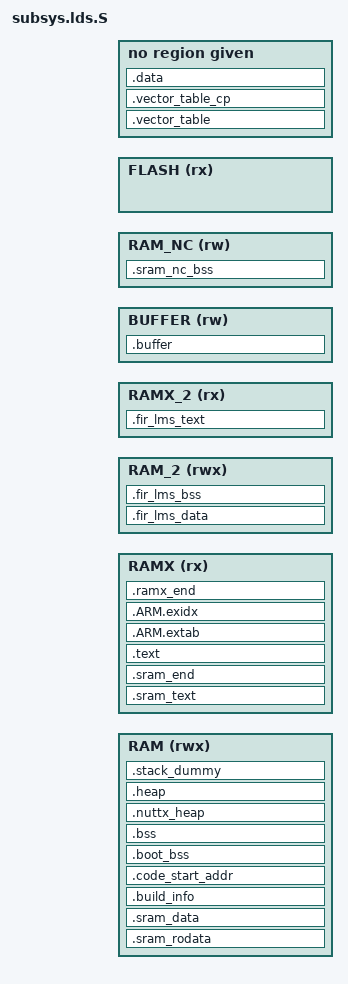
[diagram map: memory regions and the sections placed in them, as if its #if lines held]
/***************************************************************************
 *
 * Copyright 2015-2020 BES.
 * All rights reserved. All unpublished rights reserved.
 *
 * No part of this work may be used or reproduced in any form or by any
 * means, or stored in a database or retrieval system, without prior written
 * permission of BES.
 *
 * Use of this work is governed by a license granted by BES.
 * This work contains confidential and proprietary information of
 * BES. which is protected by copyright, trade secret,
 * trademark and other intellectual property rights.
 *
 ****************************************************************************/

#include "plat_addr_map.h"

#define HEAP_SECTION_SIZE			0x400
#if defined(__NuttX__)
#include "nuttx/config.h"
#define NUTTX_HEAP_SECTION_SIZE		0x10000
#ifdef HEAP_SECTION_SIZE
#undef HEAP_SECTION_SIZE
#define HEAP_SECTION_SIZE			0x10
#endif
#define STACK_SECTION_SIZE			CONFIG_IDLETHREAD_STACKSIZE
#define NUTTX_HEAP_USE_MAX          (37 * 1024)
#else
#define STACK_SECTION_SIZE			0x1100
#endif

#ifndef CP_STACK_SECTION_SIZE
#define CP_STACK_SECTION_SIZE       0x1000
#endif

#ifndef MAIN_RAM_USE_TCM
#ifndef NO_OVERLAY
#error "Overlay is NOT supported unless MAIN_RAM_USE_TCM defined"
#endif
#ifndef RAMXRET_SIZE
#define RAMXRET_SIZE				RAMRET_SIZE
#endif
#ifndef RAMX_SIZE
#define RAMX_SIZE					RAM_SIZE
#endif
#endif

#ifdef FLASH_BASE
#if !defined(OTA_BOOT_SIZE) && defined(OTA_CODE_OFFSET)
#define FLASH_REGION_BASE			(FLASH_BASE + OTA_CODE_OFFSET)
#elif defined(OTA_BOOT_OFFSET)
#define FLASH_REGION_BASE			(FLASH_BASE + OTA_BOOT_OFFSET)
#else
#define FLASH_REGION_BASE			(FLASH_BASE)
#endif

#ifndef FLASH_REGION_SIZE
#define FLASH_REGION_SIZE			(FLASH_SIZE - (FLASH_REGION_BASE - FLASH_BASE))
#endif
#endif

#ifdef MAIN_RAM_USE_TCM
#define LOAD_REGION					FLASH
#else
#define LOAD_REGION					RAM
#endif

#ifdef RAM_NC_BASE
#define REGION_VECTOR				RAM_NC
#else
#define REGION_VECTOR				RAM
#endif

/* Linker script to configure memory regions. */
MEMORY
{
#if defined(RAMRET_SIZE) && (RAMRET_SIZE > 0)
	RAM		(rwx)	: ORIGIN = RAMRET_BASE,			LENGTH = RAMRET_SIZE
	RAMX	(rx)	: ORIGIN = RAMXRET_BASE,		LENGTH = RAMXRET_SIZE
#if (SENS_FIR_LMS_SIZE > 0)
	RAM_2	(rwx)	: ORIGIN = RAMX_TO_RAM(SENS_FIR_LMS_BASE),	LENGTH = SENS_FIR_LMS_SIZE
	RAMX_2	(rx)	: ORIGIN = SENS_FIR_LMS_BASE,	LENGTH = SENS_FIR_LMS_SIZE
#endif
	BUFFER	(rw)	: ORIGIN = RAM_BASE,			LENGTH = RAM_SIZE
#else
	RAM		(rwx)	: ORIGIN = RAM_BASE,			LENGTH = RAM_SIZE
	RAMX	(rx)	: ORIGIN = RAMX_BASE,			LENGTH = RAMX_SIZE
#if (SENS_FIR_LMS_SIZE > 0)
	RAM_2	(rwx)	: ORIGIN = RAMX_TO_RAM(SENS_FIR_LMS_BASE),	LENGTH = SENS_FIR_LMS_SIZE
	RAMX_2	(rx)	: ORIGIN = SENS_FIR_LMS_BASE,	LENGTH = SENS_FIR_LMS_SIZE
#endif
#if SENS_PRI_RAM_AS_BUFFER_SECTION == 1
	BUFFER	(rw)	: ORIGIN = SENS_RAM6_BASE,	    LENGTH = (SENS_RAM6_SIZE+CODEC_VAD_MAX_BUF_SIZE)
#endif
#endif
#ifdef RAM_NC_BASE
	RAM_NC		(rw)	: ORIGIN = RAM_NC_BASE,		LENGTH = RAM_NC_SIZE
#endif
#ifdef FLASH_REGION_BASE
	FLASH 	(rx)	: ORIGIN = FLASH_REGION_BASE,	LENGTH = FLASH_REGION_SIZE
#endif
}

/* Library configurations */
#ifndef __NuttX__
GROUP(libgcc.a)
#endif

/* Linker script to place sections and symbol values. Should be used together
 * with other linker script that defines memory regions ROM and RAM.
 * It references following symbols, which must be defined in code:
 *   Reset_Handler : Entry of reset handler
 *
 * It defines following symbols, which code can use without definition:
 *   __exidx_start
 *   __exidx_end
 *   __etext
 *   __data_start__
 *   __data_end__
 *   __bss_start__
 *   __bss_end__
 *   __end__
 *   end
 *   __HeapLimit
 *   __StackLimit
 *   __StackTop
 *   __stack
 *   __free_ram
 *   __buffer_start__
 *   __buffer_end__
 *   __overlay_text_exec_start__
 *   __overlay_data_start__
 */
ENTRY(Reset_Handler)

SECTIONS
{
	.vector_table (ORIGIN(REGION_VECTOR)) (NOLOAD) :
	{
		KEEP(*(.vector_table))
		. = VECTOR_SECTION_SIZE;
		. = ALIGN(4);
		__vector_table_end__ = .;
	} > REGION_VECTOR

#if defined(CP_IN_SAME_EE) && (RAMCP_SIZE == 0)
    .vector_table_cp (NOLOAD) :
    {
        KEEP(*(.vector_table_cp))
        . = VECTOR_SECTION_SIZE;
        . = ALIGN(4);
        __vector_table_end__ = .;
    } > REGION_VECTOR
#endif

#ifdef RAM_NC_BASE
	.sram_nc_bss (NOLOAD) : AT (ADDR(.sram_nc_bss))
	{
		__sram_nc_bss_start__ = .;
		*(.sram_nc_bss*)
		*(.sync_flags_sram*)
		. = ALIGN(4);
		__sram_nc_bss_end__ = .;
	} > RAM_NC

	__ram_nc_top = ORIGIN(RAM_NC) + LENGTH(RAM_NC);
	__free_ram_nc = __ram_nc_top - __sram_nc_bss_end__;
#endif

#ifdef MAIN_RAM_USE_TCM
	__sram_text_start__ = ALIGN(ORIGIN(RAMX), 32);
	__sram_text_start_load__ = ORIGIN(LOAD_REGION);
	__sram_text_start_load_offset__ = 0;
#else
#ifdef RAM_NC_BASE
	.dummy_sram_text_start (NOLOAD) :
	{
		. = 32;
	} > RAMX
	__sram_text_start__ = ALIGN(., 32);
#else
	__sram_text_start__ = ALIGN(RAM_TO_RAMX(__vector_table_end__), 32);
#endif
	__sram_text_start_load__ = RAMX_TO_RAM(__sram_text_start__);
#endif

	.sram_text (__sram_text_start__) : AT (__sram_text_start_load__)
	{
		_stext = .;
		*(.reset_handler_subsys)
#ifdef NO_OVERLAY
#if (SENS_FIR_LMS_SIZE > 0)
        *(EXCLUDE_FILE(
			anc_fir_coeff_config_best1502x.o
			anc_fir_coeff_config_best1502p.o
			anc_ff_fir_lms.o
			arm_conj_cmplx_mult_cmplx_f32.o
			anc_optimal_tf.o
			mdf4.o
			kiss_fftwrap.o
			kiss_fftr.o
			kiss_fft.o
			anc_filter.o
			beco.o
			beco_fir_q15.o
            cmsis_dsp.o
			anc_fir_lms_aec.o
			) .text*)
			*:cmsis_dsp.o(.text*.arm_add_f32)
            *:cmsis_dsp.o(.text*.arm_copy_q31)
            *:cmsis_dsp.o(.text*.arm_conv_f32)
			*:cmsis_dsp.o(.text*.arm_rfft_fast_f32)
			*:cmsis_dsp.o(.text*.arm_fir_decimate_f32)
			*:cmsis_dsp.o(.text*.arm_biquad_cascade_df1_ex_f32)
#else
        *(.text*)
#endif
#endif
		*(.boot_text_sram*)
		*(.boot_text_flash*)
		*(.sram_text*)
		*(.fast_text_sram*)
		*(.flash_text*)

#ifndef NOSTD
		KEEP(*(.init))
		KEEP(*(.fini))

		/* .ctors */
		*crtbegin.o(.ctors)
		*crtbegin?.o(.ctors)
		*(EXCLUDE_FILE(*crtend?.o *crtend.o) .ctors)
		*(SORT(.ctors.*))
		*(.ctors)

		/* .dtors */
		*crtbegin.o(.dtors)
		*crtbegin?.o(.dtors)
		*(EXCLUDE_FILE(*crtend?.o *crtend.o) .dtors)
		*(SORT(.dtors.*))
		*(.dtors)
#endif
		. = ALIGN(4);
	} > RAMX

	.sram_end (.) : AT (LOADADDR(.sram_text) + SIZEOF(.sram_text))
	{
		. = ALIGN(32);
		__sram_text_end__ = .;
	} > RAMX

	__sram_text_seg_size__ = __sram_text_end__ - __sram_text_start__;

#ifdef NO_OVERLAY

	__text_start__ = __sram_text_end__;
	__text_load_start__ = LOADADDR(.sram_end) + SIZEOF(.sram_end);

#else

	__overlay_text_start__ = .;
	__overlay_text_exec_start__ = .;
	__overlay_load_text_start__ = LOADADDR(.sram_text) + SIZEOF(.sram_text);

	OVERLAY (__overlay_text_exec_start__) : NOCROSSREFS AT (__overlay_load_text_start__)
	{
		.overlay_text0
		{
			LONG(0);
#if defined(A2DP_DECODER_CROSS_CORE)
			*:a2dp_decoder_cc_sbc.o(.text*)
			*:sbc.o(.text*.sbc_is_stream_info_valid)
			*:sbc.o(.text*.sbc_frame_length_get)
			*:sbc.o(.text*.sbc_4bit_crc_calc)
			*:sbc.o(.text*.sbc_bits_for_mono_alloc)
			*:sbc.o(.text*.sbc_bits_for_stereo_alloc)
			*:sbc.o(.text*.sbc_header_process)
			*:sbc.o(.text*.sbc_factors_process)
			*:sbc.o(.text*.sbc_sample_extract)
			*:sbc.o(.text*.sbc_sbsamples_make)
			*:sbc.o(.text*.sbc_joint_process)
			*:sbc.o(.text*.sbc_4band_synth_filter)
			*:sbc.o(.text*.sbc_8band_synth_filter)
			*:sbc.o(.text*.sbc_decoder_state_reset)
			*:sbc.o(.text*.sbc_frame_mute)
			*:sbc.o(.text*.sbc_frames_decode)
			*:sbc.o(.text*.sbc_frames_decode_do)
			*:sbc.o(.text*.sbc_frames_decode_select_channel)
			*:sbc.o(.text*.sbc_frames_decode)
			*:sbc.o(.text*.sbc_samples_quant)
			*:sbc.o(.text*.sbc_decoder_init)
			*:sbc.o(.text*.sbc_encoder_init)
			*:sbc.o(.text*.sbc_frames_encode)
#endif
			*(.overlay_text0)
			. = ALIGN(4);
		}
		.overlay_text1
		{
			LONG(0);
#if defined(A2DP_DECODER_CROSS_CORE) && defined(A2DP_AAC_ON)
			*:a2dp_decoder_cc_aac.o(.text*)
			*:block.o(.text*.*CBlock_GetEscape*)
			*:tpdec_lib.o(.text*.*transportDec_GetBitstream*)
			*:tpdec_lib.o(.text*.*transportDec_GetAuBitsRemaining*)
			*:tpdec_latm.o(.text*.*CLatmDemux_GetValue*)
			*:tpdec_latm.o(.text*.*CLatmDemux_Read*)
			*:tpdec_lib.o(.text*.*transportDec_FillData*)
			*:tpdec_lib.o(.text*.*transportDec_ReadAccessUnit*)
			*:tpdec_lib.o(.text*.*transportDec_readHeader*)
			*:block.o(.text*.*ApplyTools*)
			*:aacdec_pns.o(.text*.*CPns_Apply*)
			*:aacdec_tns.o(.text*.*CTns_Apply*)
			*:aacdec_tns.o(.text*.*CTns_Reset*)
			*:aacdec_pns.o(.text*.*CPns_ResetData*)
			*:pulsedata.o(.text*.*CPulseData_Read*)
#if !defined(AAC_TEXT_PARTIAL_IN_FLASH)
			*:channel.o(.text*.*CChannelElement_Read*)
			*:tpdec_asc.o(.text*.*CProgramConfig_Reset*)
			*:tpdec_lib.o(.text*.*transportDec_CrcCheck*)
			*:block.o(.text*.*CBlock_FrequencyToTime*)
			*:block.o(.text*.*CBlock_ReadSectionData*)
			*:channel.o(.text*.*CChannelElement_Decode*)
			*:tpdec_lib.o(.text*.*transportDec_CrcEndReg*)
			*:aacdecoder.o(.text*.*CAacDecoder_DecodeFrame*)
			*:aac_mdct.o(.text*)
#endif

#if !defined(__SBC_FUNC_IN_ROM_VBEST2000__) && !defined(AAC_TEXT_PARTIAL_IN_FLASH)
			*:block.o(.text*.*CBlock_ReadSpectralData*)
			*:block.o(.text*.*CBlock_ScaleSpectralData*)
			*:aacdec_tns.o(.text*.*CTns_ReadDataPresentFlag*)
			*:tpdec_lib.o(.text*.*transportDec_CrcStartReg*)
			*:block.o(.text*.*CBlock_ReadScaleFactorData*)
			*:tpdec_lib.o(.text*.*transportDec_EndAccessUnit*)
			*:tpdec_latm.o(.text*.*CLatmDemux_GetNrOfSubFrames*)
			*:tpdec_lib.o(.text*.*transportDec_GetAuBitsTotal*)
			*:tpdec_asc.o(.text*.*CProgramConfig_LookupElement*)
			*:tpdec_latm.o(.text*.*CLatmDemux_GetFrameLengthInBits*)
			*:tpdec_latm.o(.text*.*CLatmDemux_ReadPayloadLengthInfo*)
			*:block.o(.text*.*CBlock_InverseQuantizeSpectralData*)
			*:channelinfo.o(.text*.*IcsRead*)
			*:aacdec_tns.o(.text*.*CTns_Read*)
			*:tpdec_lib.o(.text*.*transportDec_AdjustEndOfAccessUnit*)
			*:pulsedata.o(.text*.*CPulseData_Apply*)
			*:tpdec_asc.o(.text*.*AudioSpecificConfig_Init*)
			*:tpdec_asc.o(.text*.*AudioSpecificConfig_Parse*)
			*:tpdec_latm.o(.text*.*CLatmDemux_ReadStreamMuxConfig*)
			*:tpdec_asc.o(.text*.*getSampleRate*)
			*:tpdec_asc.o(.text*.*getAOT*)
			*:aacdecoder.o(.text*.*CAacDecoder_Init*)
			*:tpdec_asc.o(.text*.*CProgramConfig_Init*)
			*:aacdecoder_lib.o(.text*.*aacDecoder_ConfigCallback*)
			*:aacdecoder.o(.text*.*CAacDecoder_ExtPayloadParse*)
			*:stereo.o(.text*.*CJointStereo_Read*)
#endif			
			*:aac_com.o(.text*)
			*:aac_enc.o(.text*)
			*:aac_dec.o(.text*)
#endif
			*(.overlay_text1)
			. = ALIGN(4);
		}
		.overlay_text2
		{
			LONG(0);
#if defined(A2DP_DECODER_CROSS_CORE) && defined(A2DP_SCALABLE_ON)
			*:rc_decode.o(.text*)
			*:audio_int32.o(.text*)
			*:ssc_ifft.o(.text*)
			*:vector_quant.o(.text*)
			*:ssc_quant.o(.text*)
			*:ssc_pulsealloc.o(.text*)
			*:audio.o(.text*)
			*:set_sbm.o(.text*)
			*:rc_code.o(.text*)
			*:SBM_pitchBased.o(.text*)
			*:ssc_imdct.o(.text*)
			*:audio_decoder.o(.text*)
			*:SoundBooster_DRC_classic.o(.text*)
			*:ssc_cwrs.o(.text*)
			*:ssc_mode.o(.text*)
			*:ssc_math.o(.text*)
			*:ssc_lap.o(.text*)
			*:SeamlessBufferManagement.o(.text*)
			*:a2dp_decoder_cc_scalable.o(.text*)
#endif
			*(.overlay_text2)
			. = ALIGN(4);
		}
		.overlay_text3
		{
			LONG(0);
			*(.overlay_text3)
			. = ALIGN(4);
		}
		.overlay_text4
		{
			LONG(0);
			*(.overlay_text4)
			. = ALIGN(4);
		}
		.overlay_text5
		{
			LONG(0);
			*(.overlay_text5)
			. = ALIGN(4);
		}
		.overlay_text6
		{
			LONG(0);
			*(.overlay_text6)
			. = ALIGN(4);
		}
		.overlay_text7
		{
			LONG(0);
			*(.overlay_text7)
			. = ALIGN(4);
		}
		.overlay_text8
		{
			LONG(0);
			*(.overlay_text8)
			. = ALIGN(4);
		}
		.overlay_text9
		{
			LONG(0);
			*(.overlay_text9)
			. = ALIGN(4);
		}
		.overlay_text10
		{
			LONG(0);
			*(.overlay_text10)
			. = ALIGN(4);
		}
		.overlay_text11
		{
			LONG(0);
			*(.overlay_text11)
			. = ALIGN(4);
		}
		.overlay_text_last
		{
			LONG(0);
			. = ALIGN(4);
		}
	} > RAMX

	__overlay_text0_load_offset__ = __load_start_overlay_text0 - __sram_text_start_load__;
	__overlay_text1_load_offset__ = __load_start_overlay_text1 - __sram_text_start_load__;
	__overlay_text2_load_offset__ = __load_start_overlay_text2 - __sram_text_start_load__;
	__overlay_text3_load_offset__ = __load_start_overlay_text3 - __sram_text_start_load__;
	__overlay_text4_load_offset__ = __load_start_overlay_text4 - __sram_text_start_load__;
	__overlay_text5_load_offset__ = __load_start_overlay_text5 - __sram_text_start_load__;
	__overlay_text6_load_offset__ = __load_start_overlay_text6 - __sram_text_start_load__;
	__overlay_text7_load_offset__ = __load_start_overlay_text7 - __sram_text_start_load__;

	__overlay_text0_size__ = __load_stop_overlay_text0 - __load_start_overlay_text0;
	__overlay_text1_size__ = __load_stop_overlay_text1 - __load_start_overlay_text1;
	__overlay_text2_size__ = __load_stop_overlay_text2 - __load_start_overlay_text2;
	__overlay_text3_size__ = __load_stop_overlay_text3 - __load_start_overlay_text3;
	__overlay_text4_size__ = __load_stop_overlay_text4 - __load_start_overlay_text4;
	__overlay_text5_size__ = __load_stop_overlay_text5 - __load_start_overlay_text5;
	__overlay_text6_size__ = __load_stop_overlay_text6 - __load_start_overlay_text6;
	__overlay_text7_size__ = __load_stop_overlay_text7 - __load_start_overlay_text7;

	.dummy_overlay_text_end (.) (NOLOAD) : AT (ADDR(.dummy_overlay_text_end))
	{
		__overlay_text_exec_end__ = .;
	} > RAMX

	__text_start__ = ALIGN(., 32);
	__text_load_start__ = __load_stop_overlay_text_last;

#endif /* !NO_OVERLAY */

	__text_start_load_offset__ = __text_load_start__ -  __sram_text_start_load__;

	.text (__text_start__) : AT (__text_load_start__)
	{
#ifndef NO_OVERLAY
		*(.text*)
#endif
#if (RAMCP_SIZE == 0)
		*(.cp_text*)
#endif
	} > RAMX

	.ARM.extab (.) : AT (LOADADDR(.text) + SIZEOF(.text))
	{
		*(.ARM.extab* .gnu.linkonce.armextab.*)
	} > RAMX

	/* .ARM.exidx contains R_ARM_PREL31 (+-0x40000000) offset to functions, which means
	 * the session location cannot be too far away from the function addresses */
	.ARM.exidx (.) : AT (LOADADDR(.ARM.extab) + SIZEOF(.ARM.extab))
	{
		__exidx_start = .;
		*(.ARM.exidx* .gnu.linkonce.armexidx.*)
		__exidx_end = .;
	} > RAMX

	.ramx_end (.) : AT (LOADADDR(.ARM.exidx) + SIZEOF(.ARM.exidx))
	{
		. = ALIGN(32);
		__ramx_end = .;
	} > RAMX

	/* For MPU config */
	__fast_sram_text_exec_start__ = __text_start__;
	__fast_sram_text_exec_end__ = __ramx_end;

#ifdef MAIN_RAM_USE_TCM
	__text_seg_size__ = __ramx_end - __text_start__;
	__sram_rodata_start__ = ALIGN(__vector_table_end__, 32);
	__sram_rodata_start_load__ = LOADADDR(.ramx_end) + SIZEOF(.ramx_end);
	__sram_rodata_start_load_offset__ = __sram_rodata_start_load__ - __sram_text_start_load__;
#else
	__sram_rodata_start__ = ALIGN(RAMX_TO_RAM(.), 32);
	__sram_rodata_start_load__ = __sram_rodata_start__;
#endif

	.sram_rodata (__sram_rodata_start__) : AT (__sram_rodata_start_load__)
	{
		*(.boot_rodata_sram*)
		*(.sram_rodata*)
		*(.boot_rodata_flash*)
		*(.flash_rodata*)
		*(.rodata*)

		. = ALIGN(4);

#ifndef NOSTD
		KEEP(*(.eh_frame*))
#endif
		*(.note.gnu.build-id)
		. = ALIGN(32);
	} > RAM

	__etext = .;
	_etext = .;

	.sram_data (.) : AT (LOADADDR(.sram_rodata) + SIZEOF(.sram_rodata))
	{
		__sram_data_start__ = .;
		_sdata = .;
#ifdef NO_OVERLAY
		*(.data*)
#endif
		*(.boot_data*)
		*(.sram_data*)
		. = ALIGN(4);

#ifndef NOSTD
		*(vtable)

		. = ALIGN(4);
		/* preinit data */
		_sinit = ABSOLUTE(.);
		PROVIDE_HIDDEN (__preinit_array_start = .);
		KEEP(*(.preinit_array))
		PROVIDE_HIDDEN (__preinit_array_end = .);

		. = ALIGN(4);
		/* init data */
		PROVIDE_HIDDEN (__init_array_start = .);
		KEEP(*(SORT(.init_array.*)))
		KEEP(*(EXCLUDE_FILE(*opus_api.o) .init_array))
		PROVIDE_HIDDEN (__init_array_end = .);
		_einit = ABSOLUTE(.);
		. = ALIGN(4);
		/* finit data */
		PROVIDE_HIDDEN (__fini_array_start = .);
		KEEP(*(SORT(.fini_array.*)))
		KEEP(*(.fini_array))
		PROVIDE_HIDDEN (__fini_array_end = .);


		KEEP(*(.jcr*))
		. = ALIGN(4);
#endif

		__core_bridge_task_cmd_table_start = .;
		KEEP(*(.core_bridge_task_cmd_table))
		__core_bridge_task_cmd_table_end = .;
		. = ALIGN(4);
		__core_bridge_instant_cmd_table_start = .;
		KEEP(*(.core_bridge_instant_cmd_table))
		__core_bridge_instant_cmd_table_end = .;

		/* All data end */
		. = ALIGN(4);
		__sram_data_end__ = .;
		_edata = .;
	} > RAM

#ifdef MAIN_RAM_USE_TCM
	__sram_data_seg_size__ = . - __sram_rodata_start__;
#endif

#ifdef NO_OVERLAY

	__data_seg_start_load__ = LOADADDR(.sram_data) + SIZEOF(.sram_data);

#else

	__overlay_data_start__ = .;
	__load_start_overlay_data_start = LOADADDR(.sram_data) + SIZEOF(.sram_data);

	OVERLAY (__overlay_data_start__) : NOCROSSREFS AT (__load_start_overlay_data_start)
	{
		.overlay_data0
		{
            LONG(0);
#if defined(A2DP_DECODER_CROSS_CORE)
			*:a2dp_decoder_cc_sbc.o(.data* .rodata* .bss*)
#endif
			. = ALIGN(4);
		}
		.overlay_data1
		{
			LONG(0);
#if defined(A2DP_DECODER_CROSS_CORE) && defined(A2DP_AAC_ON)
			*:a2dp_decoder_cc_aac.o(.data* .rodata* .bss*)
			*:aac_com.o(.data .rodata*)
			*:aac_dec.o(.data .rodata*)
			*:aac_enc.o(.data .rodata*)
			*:block.o(.data* .rodata*)
			*:tpdec_lib.o(.data* .rodata*)
			*:tpdec_latm.o(.data* .rodata*)
			*:aacdec_pns.o(.data* .rodata*)
			*:aacdec_tns.o(.data* .rodata*)
			*:pulsedata.o(.data* .rodata*)
			*:channel.o(.data* .rodata*)
			*:tpdec_asc.o(.data* .rodata*)
			*:aacdecoder.o(.data* .rodata*)
			*:channelinfo.o(.data* .rodata*)
			*:aacdecoder_lib.o(.data* .rodata*)
			*:stereo.o(.data* .rodata*)
			*:fixpoint_math.o(.data* .rodata*)
			*:FDK_bitbuffer.o(.data* .rodata*)
#endif
			. = ALIGN(4);
		}
		.overlay_data2
		{
			LONG(0);
#if defined(A2DP_DECODER_CROSS_CORE) && defined(A2DP_SCALABLE_ON)
			*:rc_decode.o(.data* .rodata*)
			*:audio_int32.o(.data* .rodata*)
			*:ssc_ifft.o(.data* .rodata*)
			*:vector_quant.o(.data* .rodata*)
			*:ssc_quant.o(.data* .rodata*)
			*:ssc_pulsealloc.o(.data* .rodata*)
			*:audio.o(.data* .rodata*)
			*:set_sbm.o(.data* .rodata*)
			*:rc_code.o(.data* .rodata*)
			*:SBM_pitchBased.o(.data* .rodata*)
			*:ssc_imdct.o(.data* .rodata*)
			*:audio_decoder.o(.data* .rodata*)
			*:SoundBooster_DRC_classic.o(.data* .rodata*)
			*:ssc_cwrs.o(.data* .rodata*)
			*:ssc_mode.o(.data* .rodata*)
			*:ssc_math.o(.data* .rodata*)
			*:ssc_lap.o(.data* .rodata*)
			*:SeamlessBufferManagement.o(.data* .rodata*)
			*:a2dp_decoder_cc_scalable.o(.data* .rodata* .bss*)
#endif
			. = ALIGN(4);
		}
		.overlay_data3
		{
			LONG(0);
			. = ALIGN(4);
		}
		.overlay_data4
		{
			LONG(0);
			. = ALIGN(4);
		}
		.overlay_data5
		{
			LONG(0);
			. = ALIGN(4);
		}
		.overlay_data6
		{
			LONG(0);
			. = ALIGN(4);
		}
		.overlay_data7
		{
			LONG(0);
			. = ALIGN(4);
		}
		.overlay_data8
		{
			LONG(0);
			. = ALIGN(4);
		}
		.overlay_data9
		{
			LONG(0);
			. = ALIGN(4);
		}
		.overlay_data10
		{
			LONG(0);
			. = ALIGN(4);
		}
		.overlay_data11
		{
			LONG(0);
			. = ALIGN(4);
		}
		.overlay_data_last
		{
			LONG(0);
			. = ALIGN(4);
		}
	} > RAM

	__overlay_data0_load_offset__ = __load_start_overlay_data0 -  __sram_text_start_load__;
	__overlay_data1_load_offset__ = __load_start_overlay_data1 - __sram_text_start_load__;
	__overlay_data2_load_offset__ = __load_start_overlay_data2 - __sram_text_start_load__;
	__overlay_data3_load_offset__ = __load_start_overlay_data3 - __sram_text_start_load__;
	__overlay_data4_load_offset__ = __load_start_overlay_data4 - __sram_text_start_load__;
	__overlay_data5_load_offset__ = __load_start_overlay_data5 - __sram_text_start_load__;
	__overlay_data6_load_offset__ = __load_start_overlay_data6 - __sram_text_start_load__;
	__overlay_data7_load_offset__ = __load_start_overlay_data7 - __sram_text_start_load__;

	__overlay_data0_size__ = __load_stop_overlay_data0 - __load_start_overlay_data0;
	__overlay_data1_size__ = __load_stop_overlay_data1 - __load_start_overlay_data1;
	__overlay_data2_size__ = __load_stop_overlay_data2 - __load_start_overlay_data2;
	__overlay_data3_size__ = __load_stop_overlay_data3 - __load_start_overlay_data3;
	__overlay_data4_size__ = __load_stop_overlay_data4 - __load_start_overlay_data4;
	__overlay_data5_size__ = __load_stop_overlay_data5 - __load_start_overlay_data5;
	__overlay_data6_size__ = __load_stop_overlay_data6 - __load_start_overlay_data6;
	__overlay_data7_size__ = __load_stop_overlay_data7 - __load_start_overlay_data7;

	.dummy_overlay_data_end (.) (NOLOAD) : AT (ADDR(.dummy_overlay_data_end))
	{
		__overlay_data_end__ = .;
	} > RAM

	__data_seg_start_load__ = __load_stop_overlay_data_last;

#endif /* !NO_OVERLAY */

	__data_start_load_offset__ = __data_seg_start_load__ - __sram_text_start_load__;

	.data (.) : AT (__data_seg_start_load__)
	{
		__data_start__ = .;
#ifndef NO_OVERLAY
		*(.data*)
		*(.rodata*)
#endif
#if (RAMCP_SIZE == 0)
		*(.cp_data*)
#endif
		__data_end__ = .;
	}

	.build_info (.) : AT (LOADADDR(.data) + SIZEOF(.data))
	{
		KEEP(*(.build_info))
		. = ALIGN(4);
		__ram_end__ = .;
	} > RAM = 0x00000000

#ifdef MAIN_RAM_USE_TCM
	__data_seg_size__ = . - __data_start__;
#endif
#if (SENS_FIR_LMS_SIZE > 0)
    __fir_lms_text_start_load = LOADADDR(.build_info) + SIZEOF(.build_info);
    .fir_lms_text (ORIGIN(RAMX_2)) : AT (__fir_lms_text_start_load)
	{
		__fir_lms_text_start = .;
		*(.fir_lms_text_section)
		*:anc_fir_coeff_config_best1502x.o(.text*)
		*:anc_fir_coeff_config_best1502p.o(.text*)
		*:anc_ff_fir_lms.o(.text*)
		*:arm_conj_cmplx_mult_cmplx_f32.o(.text*)
		*:anc_optimal_tf.o(.text*)
		*:mdf4.o(.text*)
		*:kiss_fftwrap.o(.text*)
		*:kiss_fftr.o(.text*)
		*:kiss_fft.o(.text*)
		*:anc_filter.o(.text*)
		*:beco.o(.text*)
		*:beco_fir_q15.o(.text*)
		*:cmsis_dsp.o(.text*)
		*:anc_fir_lms_aec.o(.text*)
		. = ALIGN(4);
		__fir_lms_text_end = .;
	} > RAMX_2

    __fir_lms_data_start_load = LOADADDR(.fir_lms_text) + SIZEOF(.fir_lms_text);
    .fir_lms_data (RAMX_TO_RAM(.)): AT (__fir_lms_data_start_load)
	{
		__fir_lms_data_start = .;
		*(.fir_lms_data_section)
		. = ALIGN(4);
		__fir_lms_data_end = .;
	} > RAM_2

	.fir_lms_bss (.) (NOLOAD):
	{
		__fir_lms_bss_start = .;
		*(.fir_lms_bss_section)
		. = ALIGN(4);
		__fir_lms_bss_end = .;
	} > RAM_2
    __fir_lms_data_end_load = LOADADDR(.fir_lms_data) + SIZEOF(.fir_lms_data);
	__ram_2_limit = ORIGIN(RAM_2) + LENGTH(RAM_2);
	ASSERT(__ram_2_limit >= __fir_lms_bss_end, "region RAM_2 overflowed")
#else
    __fir_lms_data_end_load = LOADADDR(.build_info) + SIZEOF(.build_info);
#endif
	/* The following section be the last loaded section */
	.code_start_addr (__ram_end__) : AT (__fir_lms_data_end_load)
	{
#ifdef MAIN_RAM_USE_TCM
		__code_info_offset__ = LOADADDR(.code_start_addr) - __sram_text_start_load__;
#ifdef NO_OVERLAY
		LONG(0);
#else
		LONG(1);
		KEEP(*(.code_overlay_map))
#endif
		KEEP(*(.code_seg_map))
		LONG(ABSOLUTE(RAMX_TO_RAM(__code_info_offset__)));
#else
		LONG(ABSOLUTE(RAMX_TO_RAM(__sram_text_start__)));
#endif
	} > RAM

	.boot_bss (.) (NOLOAD) :
	{
		. = ALIGN(4);
		__boot_bss_sram_start__ = .;
		*(.boot_bss*)
		. = ALIGN(4);
		__boot_bss_sram_end__ = .;
#if defined(CP_IN_SAME_EE) && (RAMCP_SIZE == 0)
		. = ALIGN(64);
		__cp_stack_limit = .;
		. += CP_STACK_SECTION_SIZE;
		__cp_stack_top = .;
#endif
	} > RAM

	.bss (.) (NOLOAD) :
	{
		. = ALIGN(4);
		__bss_start__ = .;
		_sbss = .;
		*(.bss*)
#if (RAMCP_SIZE == 0)
		*(.cp_bss*)
#endif
		*(.reboot_param*)
		*(.boot_bss*)
		*(.sram_bss*)
		*(COMMON)
#if defined(CONFIG_SMP)
		. = ALIGN(64);
		__cp_stack_limit = .;
		. += 1024;	/* just used for system_cp_reset_handler's stack */
		__cp_stack_top = .;
#endif
		. = ALIGN(4);
		__bss_end__ = .;
		_ebss = .;
	} > RAM

#if defined(__NuttX__) && defined(CONFIG_USE_BES_BT_STACK)
	.nuttx_heap (.) (NOLOAD) :
	{
		_nuttx_heap_start = .;
		. = ALIGN(8);
		. += NUTTX_HEAP_SECTION_SIZE;
		. = ALIGN(8);
		_nuttx_heap_end = .;
	} > RAM
#endif
	.heap (.) (NOLOAD) :
	{
		. = ALIGN(8);
		__HeapBase = .;
		__end__ = .;
		end = __end__;
		. += HEAP_SECTION_SIZE;
		. = ALIGN(8);
		__HeapLimit = .;
	} > RAM

	/* .stack_dummy section doesn't contains any symbols. It is only
	 * used for linker to calculate size of stack sections, and assign
	 * values to stack symbols later */
	.stack_dummy (.) (COPY) :
	{
		. = STACK_SECTION_SIZE;
		. = ALIGN(8);
	} > RAM

#if defined(RAMRET_SIZE) && (RAMRET_SIZE > 0) || (SENS_PRI_RAM_AS_BUFFER_SECTION == 1)
	.buffer (ORIGIN(BUFFER)) (NOLOAD) :
	{
		__buffer_start__ = .;
		*(.buffer_section)
		__buffer_end__ = LENGTH(BUFFER);
	} > BUFFER
#else
	__buffer_start__ = .;
	__buffer_end__ = __buffer_start__;
#endif

	/* Set stack top to end of RAM, and stack limit move down by
	 * size of stack_dummy section */
	__StackTop = ORIGIN(RAM) + LENGTH(RAM);
	__StackLimit = __StackTop - SIZEOF(.stack_dummy);
	PROVIDE(__stack = __StackTop);
	/* Check if data + heap + stack exceeds RAM limit */
	ASSERT(__StackLimit >= __HeapLimit, "region RAM overflowed with stack")
	__free_ram = __StackLimit - __HeapLimit;

#ifdef __NuttX__
	ASSERT(__free_ram >= NUTTX_HEAP_USE_MAX, "nuttx heap is not enough")
#endif

	__mem_pool_start__ = __HeapLimit;
	__mem_pool_end__ = __StackLimit;

#if defined(__NuttX__) && !defined(CONFIG_USE_BES_BT_STACK)
	_nuttx_heap_start = __mem_pool_start__;
	_nuttx_heap_end = __mem_pool_end__ - 4;
#endif

#ifdef MAIN_RAM_USE_TCM
	__ramx_top = ORIGIN(RAMX) + LENGTH(RAMX);
	__free_ramx = __ramx_top - __ramx_end;
#endif
}
